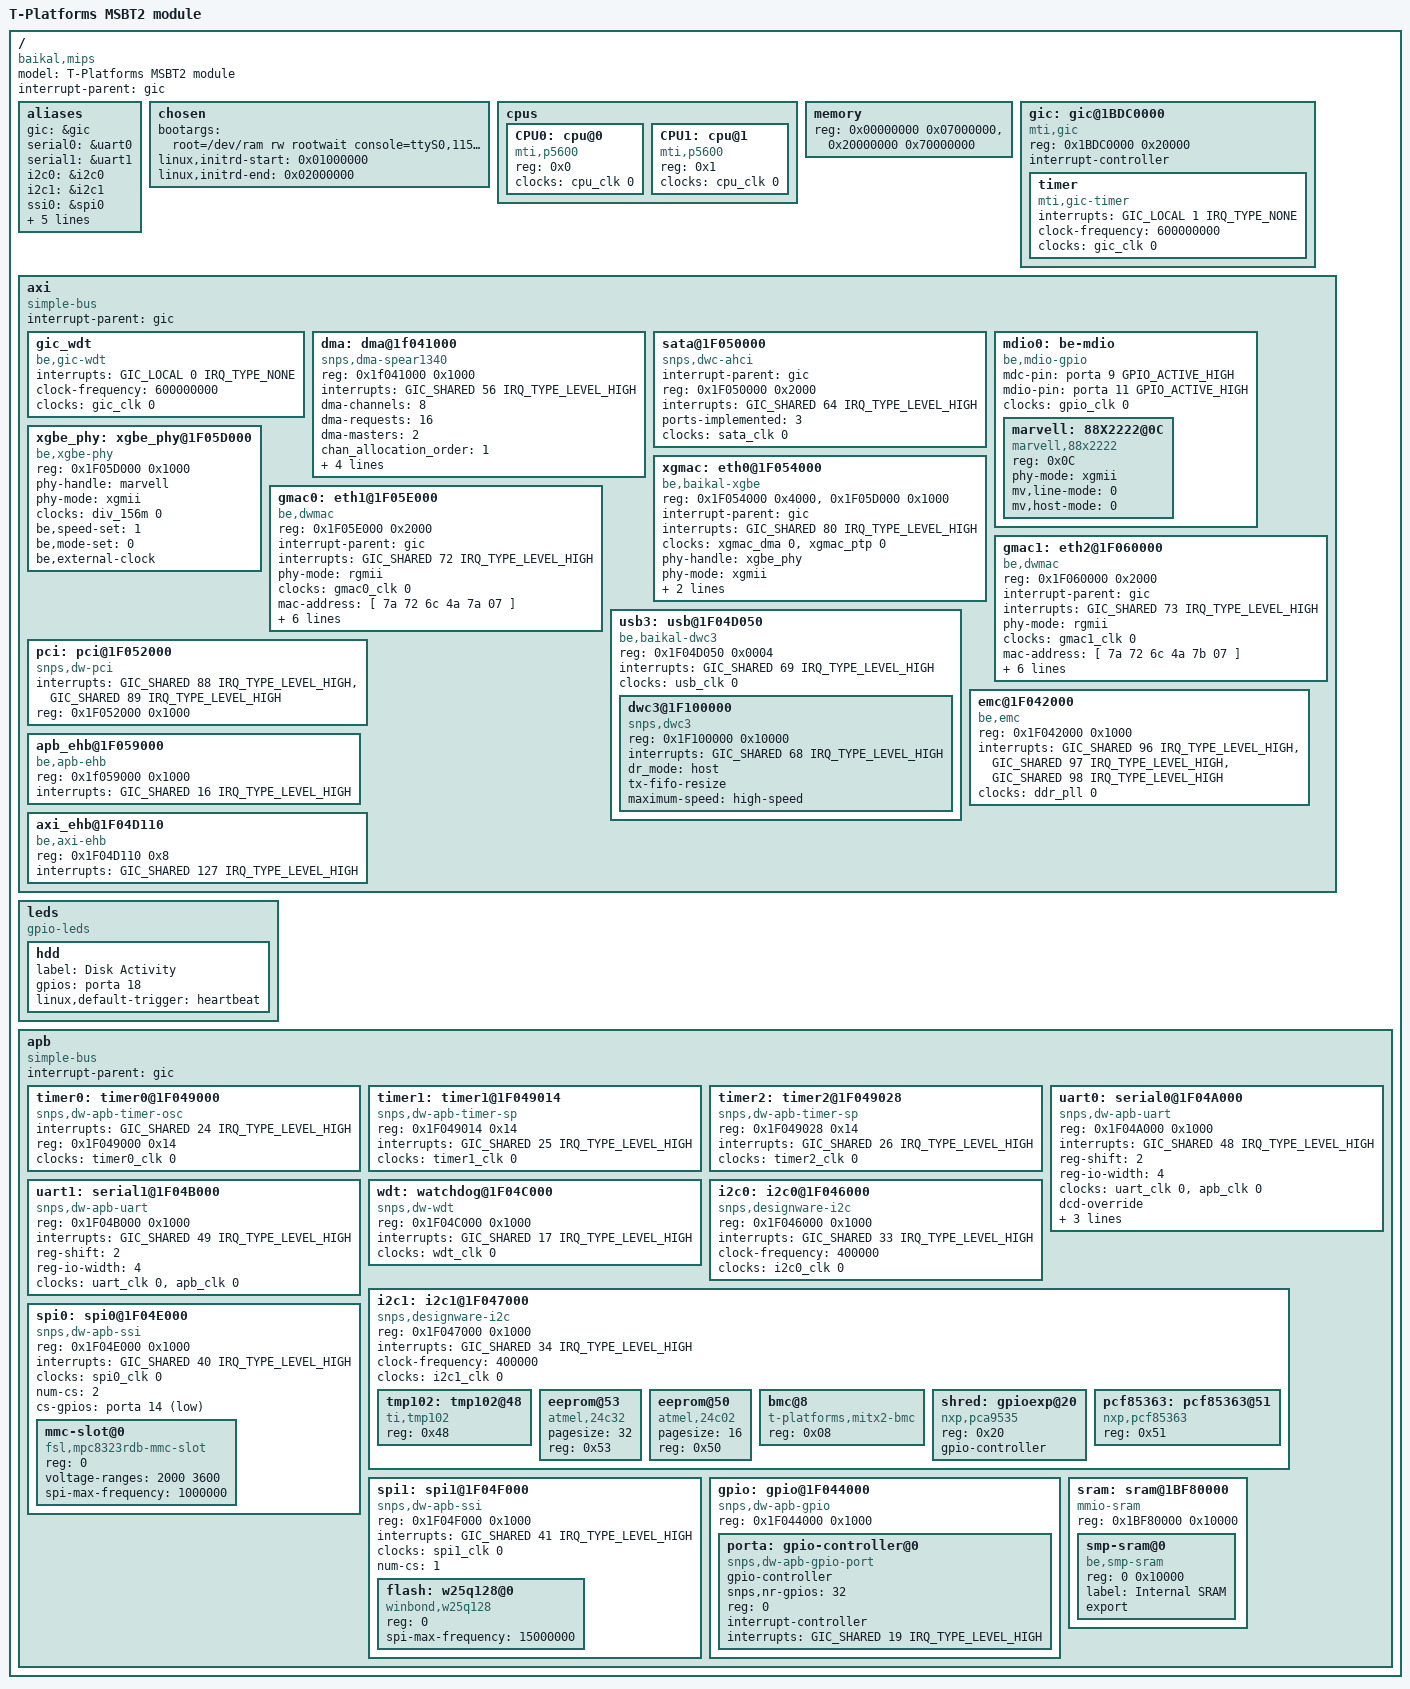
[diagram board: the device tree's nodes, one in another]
/*
 * Baikal-T BFK2 board device tree.
 *
 * Copyright (C) 2014-2016  Baikal Electronics JSC
 *
 * This program is free software; you can redistribute it and/or
 * modify it under the terms of the GNU General Public License
 * as published by the Free Software Foundation; either version 2
 * of the License, or (at your option) any later version.
 *
 * This program is distributed in the hope that it will be useful,
 * but WITHOUT ANY WARRANTY; without even the implied warranty of
 * MERCHANTABILITY or FITNESS FOR A PARTICULAR PURPOSE.  See the
 * GNU General Public License for more details.
 *
 * You should have received a copy of the GNU General Public License
 * along with this program; if not, write to the Free Software
 * Foundation, Inc., 51 Franklin Street, Fifth Floor, Boston, MA  02110-1301, USA.
 */

#include <dt-bindings/interrupt-controller/mips-gic.h>
#include <dt-bindings/gpio/gpio.h>

/dts-v1/;

/include/ "baikal_t1_clocks.dtsi"

/ {
	model = "T-Platforms MSBT2 module";
	compatible = "baikal,mips";
	#address-cells = <1>;
	#size-cells = <1>;
	interrupt-parent = <&gic>;

	aliases {
		gic = &gic;
		serial0 = &uart0;
		serial1 = &uart1;
		i2c0 = &i2c0;
		i2c1 = &i2c1;
		ssi0 = &spi0;
		ssi1 = &spi1;
		ethernet0 = &xgmac;
		ethernet1 = &gmac0;
		ethernet2 = &gmac1;
		mdio-gpio0 = &mdio0;
	};

	chosen {
        bootargs = "root=/dev/ram rw rootwait console=ttyS0,115200n8 earlyprintk=uart8250,mmio32,0x1F04A000,115200 maxcpus=2 nohtw";
		linux,initrd-start = <0x01000000>;
		linux,initrd-end   = <0x02000000>;
	};

	cpus {
		#address-cells = <1>;
		#size-cells = <0>;

		CPU0: cpu@0 {
			device_type = "cpu";
			compatible = "mti,p5600";
			reg = <0x0>;
			clocks = <&cpu_clk 0>;
			clock-names = "cpuclk";
		};

		CPU1: cpu@1 {
			device_type = "cpu";
			compatible = "mti,p5600";
			reg = <0x1>;
			clocks = <&cpu_clk 0>;
			clock-names = "cpuclk";
		};
	};

	memory {
		device_type = "memory";
		reg = <0x00000000 0x07000000>,
		      <0x20000000 0x70000000>;
	};

	/* reserved-memory { */
	/* 	#address-cells = <1>; */
	/* 	#size-cells = <1>; */
	/* 	ranges; */

	/* 	display_reserved: framebuffer@0x07000000 { */
	/* 		reg = <0x07000000 0x01000000>; */
	/* 	}; */
	/* }; */

	gic: gic@1BDC0000 {
		compatible = "mti,gic";
		reg = <0x1BDC0000 0x20000>;

		interrupt-controller;
		#interrupt-cells = <3>;

		timer:timer {
			compatible = "mti,gic-timer";
			interrupts = <GIC_LOCAL 1 IRQ_TYPE_NONE>;
			clock-frequency = <600000000>;
			clocks = <&gic_clk 0>;
			clock-names = "gicclk";
		};
	};
	axi {
		compatible = "simple-bus";
		#address-cells = <1>;
		#size-cells = <1>;
		interrupt-parent = <&gic>;

		ranges;

		gic_wdt:gic_wdt {
			compatible = "be,gic-wdt";
			interrupts = <GIC_LOCAL 0 IRQ_TYPE_NONE>;
			clock-frequency = <600000000>;
			clocks = <&gic_clk 0>;
			clock-names = "gicclk";
		};

		dma: dma@1f041000 {
			compatible = "snps,dma-spear1340";
			reg = <0x1f041000 0x1000>;
			interrupts = <GIC_SHARED 56 IRQ_TYPE_LEVEL_HIGH>;
			dma-channels = <8>;
			dma-requests = <16>;
			dma-masters = <2>;
			#dma-cells = <3>;
			chan_allocation_order = <1>;
			chan_priority = <1>;
			block_size = <0xfff>;
			data_width = <3 3 0 0>;
			clocks = <&dma_clk 0>;
			clock-names = "hclk";
		};

		sata@1F050000 {
			interrupt-parent = <&gic>;
			compatible = "snps,dwc-ahci", "generic-ahci";
			reg = <0x1F050000 0x2000>;
			interrupts = <GIC_SHARED 64 IRQ_TYPE_LEVEL_HIGH>;
			ports-implemented = <3>;
			clocks = <&sata_clk 0>;
			clock-names = "sataclk";
		};

		mdio0: be-mdio {
			compatible = "be,mdio-gpio";
			#address-cells = <1>;
			#size-cells = <0>;
			mdc-pin = <&porta 9 GPIO_ACTIVE_HIGH>;
			mdio-pin = <&porta 11 GPIO_ACTIVE_HIGH>;
			clocks = <&gpio_clk 0>;
			clock-names = "gpioclk";

			marvell:88X2222@0C {
				compatible = "marvell,88x2222", "ethernet-phy-ieee802.3-c45";
				reg = <0x0C>;
				phy-mode = "xgmii";
				mv,line-mode = <0>; /* 10GBASE-R (0x71) */
				mv,host-mode = <0>; /* 10GBASE-R (0x71) */
			};
		};

		xgbe_phy: xgbe_phy@1F05D000 {
			compatible = "be,xgbe-phy", "ethernet-phy-ieee802.3-c45";
			reg = <0x1F05D000 0x1000>;
			phy-handle = <&marvell>;
			phy-mode = "xgmii";
			clocks = <&div_156m 0>;
			clock-names = "xgbe_clk";
			be,speed-set = <1>;
			be,mode-set = <0>;
			be,external-clock;
		};

		xgmac: eth0@1F054000 {
			compatible = "be,baikal-xgbe";
			reg = <0x1F054000 0x4000>,
			      <0x1F05D000 0x1000>;
			interrupt-parent = <&gic>;
			interrupts = <GIC_SHARED 80 IRQ_TYPE_LEVEL_HIGH>;
			clocks = <&xgmac_dma 0>, <&xgmac_ptp 0>;
			clock-names = "dma_clk", "ptp_clk";
			phy-handle = <&xgbe_phy>;
			phy-mode = "xgmii";
			mac-address = [ 00 20 13 ba 1c a1 ];
			local-mac-address = [ 00 20 13 ba 1c a1 ];
		};

		gmac0: eth1@1F05E000 {
			compatible = "be,dwmac", "snps,dwmac-3.710", "snps,dwmac";
			reg = <0x1F05E000 0x2000>;
			interrupt-parent = <&gic>;
			interrupts = <GIC_SHARED 72 IRQ_TYPE_LEVEL_HIGH>;
			interrupt-names = "macirq";
			phy-mode = "rgmii";
			clocks = <&gmac0_clk 0>;
			clock-names = "stmmaceth";
			mac-address = [ 7a 72 6c 4a 7a 07 ];
			local-mac-address = [ 7a 72 6c 4a 7a 07 ];
			txd0-skew-ps = <0>;
			txd1-skew-ps = <0>;
			txd2-skew-ps = <0>;
			txd3-skew-ps = <0>;
			txc-skew-ps  = <0xff>;
		};

		gmac1: eth2@1F060000 {
			compatible = "be,dwmac", "snps,dwmac-3.710", "snps,dwmac";
			reg = <0x1F060000 0x2000>;
			interrupt-parent = <&gic>;
			interrupts = <GIC_SHARED 73 IRQ_TYPE_LEVEL_HIGH>;
			interrupt-names = "macirq";
			phy-mode = "rgmii";
			clocks = <&gmac1_clk 0>;
			clock-names = "stmmaceth";
			mac-address = [ 7a 72 6c 4a 7b 07 ];
			local-mac-address = [ 7a 72 6c 4a 7b 07 ];
			txd0-skew-ps = <0>;
			txd1-skew-ps = <0>;
			txd2-skew-ps = <0>;
			txd3-skew-ps = <0>;
			txc-skew-ps  = <0xff>;
		};

		usb3: usb@1F04D050 {
			compatible = "be,baikal-dwc3";

			reg = <0x1F04D050 0x0004>;
			interrupts = <GIC_SHARED 69 IRQ_TYPE_LEVEL_HIGH>;

			#address-cells = <1>;
			#size-cells = <1>;

			clocks = <&usb_clk 0>;
			clock-names = "usb";

			ranges;

			dwc3@1F100000 {
					compatible = "snps,dwc3", "synopsys,dwc3";
					reg = <0x1F100000 0x10000>;
					interrupts = <GIC_SHARED 68 IRQ_TYPE_LEVEL_HIGH>;
					dr_mode = "host";

					tx-fifo-resize;

					maximum-speed = "high-speed";
			};
		};

		pci: pci@1F052000 {
			compatible = "snps,dw-pci";
			interrupts = <GIC_SHARED 88 IRQ_TYPE_LEVEL_HIGH>,
				<GIC_SHARED 89 IRQ_TYPE_LEVEL_HIGH>;
			reg = <0x1F052000 0x1000>;
		};

		emc@1F042000 {
			compatible = "be,emc", "be,memory-controller";
			reg = <0x1F042000 0x1000>;
			interrupts = <GIC_SHARED 96 IRQ_TYPE_LEVEL_HIGH>,
						 <GIC_SHARED 97 IRQ_TYPE_LEVEL_HIGH>,
						 <GIC_SHARED 98 IRQ_TYPE_LEVEL_HIGH>;
			clocks = <&ddr_pll 0>;
			clock-names = "ddrclk";
		};

		apb_ehb@1F059000 {
			compatible = "be,apb-ehb";
			reg = <0x1f059000 0x1000>;
			interrupts = <GIC_SHARED 16 IRQ_TYPE_LEVEL_HIGH>;
		};

		axi_ehb@1F04D110 {
			compatible = "be,axi-ehb";
			reg = <0x1F04D110 0x8>;
			interrupts = <GIC_SHARED 127 IRQ_TYPE_LEVEL_HIGH>;
		};
	};

  leds {
    compatible = "gpio-leds";
    hdd {
      label = "Disk Activity";
      gpios = <&porta 18 GPIO_ACTIVE_HIGH>;
      linux,default-trigger = "heartbeat";
    };
    
    /* fault { */
    /*   gpios = <&porta 18 GPIO_ACTIVE_HIGH>; */
    /*   /\* Keep LED on if BIOS detected hardware fault *\/ */
    /* default-state = "off"; */
    /* }; */
  };

	apb {
		compatible = "simple-bus";
		#address-cells = <1>;
		#size-cells = <1>;
		interrupt-parent = <&gic>;

		ranges;

		timer0: timer0@1F049000 {
			compatible = "snps,dw-apb-timer-osc";
			interrupts = <GIC_SHARED 24 IRQ_TYPE_LEVEL_HIGH>;
			reg = <0x1F049000 0x14>;
			clocks = <&timer0_clk 0>;
			clock-names = "timer";
		};

		timer1: timer1@1F049014 {
			compatible = "snps,dw-apb-timer-sp";
			reg = <0x1F049014 0x14>;
			interrupts = <GIC_SHARED 25 IRQ_TYPE_LEVEL_HIGH>;
			clocks = <&timer1_clk 0>;
			clock-names = "timer";
		};

		timer2: timer2@1F049028 {
			compatible = "snps,dw-apb-timer-sp";
			reg = <0x1F049028 0x14>;
			interrupts = <GIC_SHARED 26 IRQ_TYPE_LEVEL_HIGH>;
			clocks = <&timer2_clk 0>;
			clock-names = "timer";
		};

		uart0: serial0@1F04A000 {
			compatible = "snps,dw-apb-uart";
			reg = <0x1F04A000 0x1000>;
			interrupts = <GIC_SHARED 48 IRQ_TYPE_LEVEL_HIGH>;
			reg-shift = <2>;
			reg-io-width = <4>;
			clocks = <&uart_clk 0>, <&apb_clk 0>;
			clock-names = "baudclk", "apb_pclk";
//			snps,uart-16550-compatible;
			dcd-override;
			dsr-override;
			cts-override;
			ri-override;
		};

		uart1: serial1@1F04B000 {
			compatible = "snps,dw-apb-uart";
			reg = <0x1F04B000 0x1000>;
			interrupts = <GIC_SHARED 49 IRQ_TYPE_LEVEL_HIGH>;
			reg-shift = <2>;
			reg-io-width = <4>;
			clocks = <&uart_clk 0>, <&apb_clk 0>;
			clock-names = "baudclk", "apb_pclk";
    };

		wdt: watchdog@1F04C000 {
			compatible = "snps,dw-wdt";
			reg = <0x1F04C000 0x1000>;
			interrupts = <GIC_SHARED 17 IRQ_TYPE_LEVEL_HIGH>;
			clocks = <&wdt_clk 0>;
			clock-names = "wdtclk";
		};

		i2c0: i2c0@1F046000 {
			#address-cells = <1>;
			#size-cells = <0>;
			compatible = "snps,designware-i2c";
			reg = <0x1F046000 0x1000>;
			interrupts = <GIC_SHARED 33 IRQ_TYPE_LEVEL_HIGH>;
			clock-frequency = <400000>;
			clocks = <&i2c0_clk 0>;
			clock-names = "i2c0clk";
		};

		i2c1: i2c1@1F047000 {
			#address-cells = <1>;
			#size-cells = <0>;
			compatible = "snps,designware-i2c";
			reg = <0x1F047000 0x1000>;
			interrupts = <GIC_SHARED 34 IRQ_TYPE_LEVEL_HIGH>;
			clock-frequency = <400000>;
			clocks = <&i2c1_clk 0>;
			clock-names = "i2c1clk";

			tmp102: tmp102@48 {
				compatible = "ti,tmp102";
				reg = <0x48>;
			};

			eeprom@53 {
				compatible = "atmel,24c32";
				pagesize = <32>;
				reg = <0x53>;
			};

			eeprom@50 {
				compatible = "atmel,24c02";
				pagesize = <16>;
				reg = <0x50>;
			};

			bmc@8 {
				compatible = "t-platforms,mitx2-bmc";
				reg = <0x08>;
			};

			shred: gpioexp@20 {
				compatible = "nxp,pca9535";
				reg = <0x20>;
				gpio-controller;
				#gpio-cells = <2>;
			};

			pcf85363: pcf85363@51 {
				compatible = "nxp,pcf85363";
				reg = <0x51>;
			};
		};

		spi0: spi0@1F04E000 {
			#address-cells = <1>;
			#size-cells = <0>;
			compatible = "snps,dw-apb-ssi", "snps,dw-spi";
			reg = <0x1F04E000 0x1000>;
			interrupts = <GIC_SHARED 40 IRQ_TYPE_LEVEL_HIGH>;
			clocks = <&spi0_clk 0>;
			clock-names = "spi0clk";
			num-cs = <2>;
      cs-gpios = <&porta 14 GPIO_ACTIVE_LOW>;
      
      mmc-slot@0 {
        compatible = "fsl,mpc8323rdb-mmc-slot",
        "mmc-spi-slot";
        reg = <0>;
        //gpios = <&porta 15 GPIO_ACTIVE_LOW
        //&porta 15 GPIO_ACTIVE_HIGH>;
        voltage-ranges = <2000 3600>;
        spi-max-frequency = <1000000>;
        //interrupts = <GIC_SHARED 19 IRQ_TYPE_LEVEL_HIGH>;
      };
		};

		spi1: spi1@1F04F000 {
			#address-cells = <1>;
			#size-cells = <0>;
			compatible = "snps,dw-apb-ssi", "snps,dw-spi";
			reg = <0x1F04F000 0x1000>;
			interrupts = <GIC_SHARED 41 IRQ_TYPE_LEVEL_HIGH>;
			clocks = <&spi1_clk 0>;
			clock-names = "spi1clk";
			num-cs = <1>;

      /* spidev1@0 { */
      /*   compatible = "spidev"; */
      /*   spi-max-frequency = <1000000>; */
      /*   reg = <0>; */
      /* }; */

      flash: w25q128@0 {
        #address-cells = <1>;
        #size-cells = <1>;
        compatible = "winbond,w25q128";
        reg = <0>;
        spi-max-frequency = <15000000>;
      };
  
    };
    
		gpio: gpio@1F044000 {
			compatible = "snps,dw-apb-gpio";
			reg = <0x1F044000 0x1000>;
			#address-cells = <1>;
			#size-cells = <0>;

			porta: gpio-controller@0 {
				compatible = "snps,dw-apb-gpio-port";
				#gpio-cells = <2>;
				gpio-controller;
				snps,nr-gpios = <32>;
				reg = <0>;
				#interrupt-cells = <2>;
				interrupt-controller;
				interrupts = <GIC_SHARED 19 IRQ_TYPE_LEVEL_HIGH>;
			};
		};

		/* 64 KiB SRAM at address 0x1BF80000 */
		sram: sram@1BF80000 {
			compatible = "mmio-sram";
			reg = <0x1BF80000 0x10000>;

			#address-cells = <1>;
			#size-cells = <1>;

			ranges = <0 0x1BF80000 0x10000>;

			smp-sram@0 {
				compatible = "be,smp-sram";
				reg = <0 0x10000>;
				label="Internal SRAM";
				export;
			};
		};
	};
};
